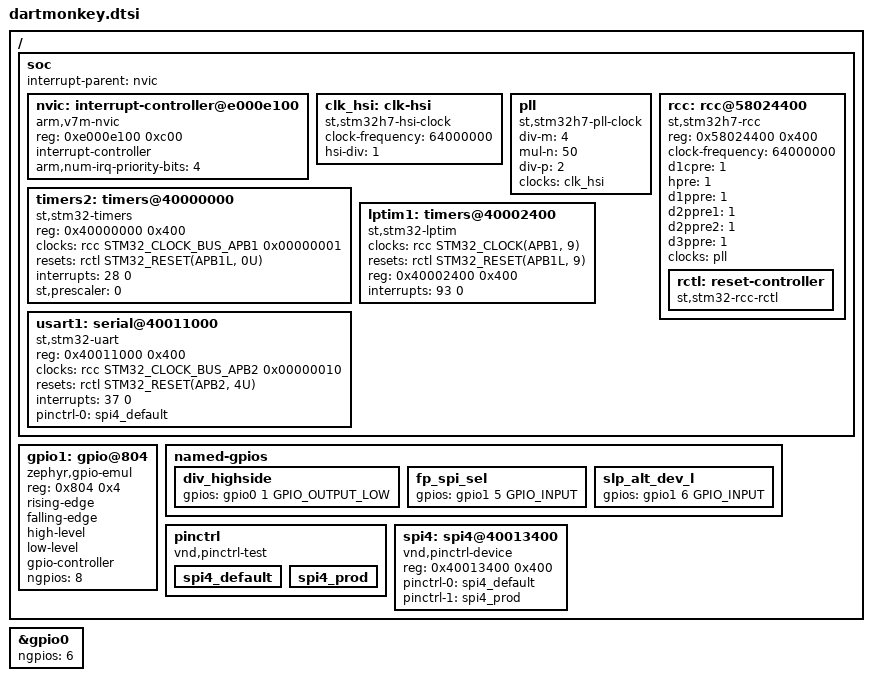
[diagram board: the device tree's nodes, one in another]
/* Copyright 2024 The ChromiumOS Authors
 * Use of this source code is governed by a BSD-style license that can be
 * found in the LICENSE file.
 */

#include <zephyr/dt-bindings/clock/stm32h7_clock.h>
#include <zephyr/dt-bindings/reset/stm32h7_reset.h>
#include "../native_sim.overlay"

/ {
	soc {
		#address-cells = <1>;
		#size-cells = <1>;
		interrupt-parent = <&nvic>;
		ranges;

		nvic: interrupt-controller@e000e100 {
			#address-cells = <1>;
			compatible = "arm,v7m-nvic";
			reg = <0xe000e100 0xc00>;
			interrupt-controller;
			#interrupt-cells = <2>;
			arm,num-irq-priority-bits = <4>;
		};

		clk_hsi: clk-hsi {
			#clock-cells = <0>;
			compatible = "st,stm32h7-hsi-clock";
			clock-frequency = <64000000>;
			hsi-div = <1>;
			status = "okay";
		};

		pll: pll {
			#clock-cells = <0>;
			compatible = "st,stm32h7-pll-clock";
			status = "okay";
			div-m = <4>;
			mul-n = <50>;
			div-p = <2>;
			clocks = <&clk_hsi>;
		};

		rcc: rcc@58024400 {
			compatible = "st,stm32h7-rcc";
			#clock-cells = <2>;
			reg = <0x58024400 0x400>;
			clock-frequency = <64000000>;
			d1cpre = <1>;
			hpre = <1>;
			d1ppre = <1>;
			d2ppre1 = <1>;
			d2ppre2 = <1>;
			d3ppre = <1>;
			clocks = <&pll>;

			rctl: reset-controller {
				compatible = "st,stm32-rcc-rctl";
				#reset-cells = <1>;
			};
		};

		timers2: timers@40000000 {
			compatible = "st,stm32-timers";
			reg = <0x40000000 0x400>;
			clocks = <&rcc STM32_CLOCK_BUS_APB1 0x00000001>;
			resets = <&rctl STM32_RESET(APB1L, 0U)>;
			interrupts = <28 0>;
			interrupt-names = "global";
			st,prescaler = <0>;
			status = "okay";
		};

		usart1: serial@40011000 {
			compatible = "st,stm32-uart";
			reg = <0x40011000 0x400>;
			clocks = <&rcc STM32_CLOCK_BUS_APB2 0x00000010>;
			resets = <&rctl STM32_RESET(APB2, 4U)>;
			interrupts = <37 0>;
			pinctrl-0 = <&spi4_default>;
			pinctrl-names = "default";
			status = "okay";
		};

		lptim1: timers@40002400 {
			compatible = "st,stm32-lptim";
			clocks = <&rcc STM32_CLOCK(APB1, 9)>;
			resets = <&rctl STM32_RESET(APB1L, 9)>;
			#address-cells = <1>;
			#size-cells = <0>;
			reg = <0x40002400 0x400>;
			interrupts = <93 0>;
			interrupt-names = "wakeup";
			status = "okay";
		};
	};

	gpio1: gpio@804 {
		status = "okay";
		compatible = "zephyr,gpio-emul";
		reg = <0x804 0x4>;
		rising-edge;
		falling-edge;
		high-level;
		low-level;
		gpio-controller;
		#gpio-cells = <2>;
		ngpios = <8>;
	};

	named-gpios {
		div_highside: div_highside {
			gpios = <&gpio0 1 GPIO_OUTPUT_LOW>;
		};

		fp_spi_sel: fp_spi_sel {
			gpios = <&gpio1 5 GPIO_INPUT>;
		};

		slp_alt_dev_l: slp_alt_dev_l {
			gpios = <&gpio1 6 GPIO_INPUT>;
		};
	};

	pinctrl: pinctrl {
		compatible = "vnd,pinctrl-test";

		spi4_default: spi4_default {
		};

		spi4_prod: spi4_prod {
		};
	};

	spi4: spi4@40013400 {
		compatible = "vnd,pinctrl-device";
		reg = <0x40013400 0x400>;
		pinctrl-0 = <&spi4_default>;
		pinctrl-1 = <&spi4_prod>;
		pinctrl-names = "default", "prod";
		status = "okay";
	};
};

&gpio0 {
	ngpios = <6>;
};
